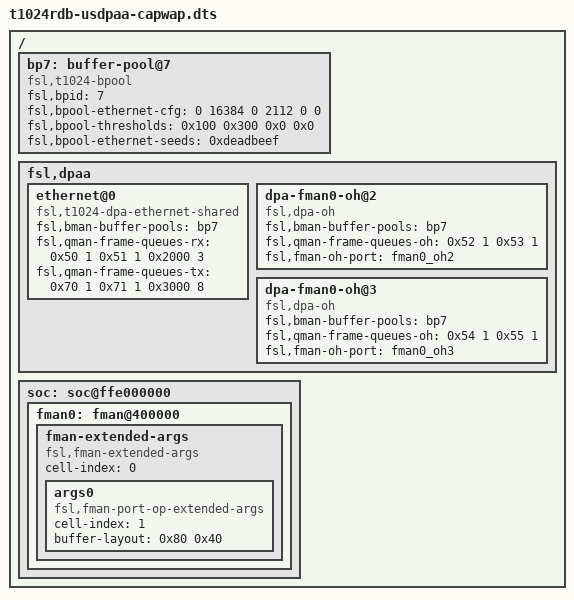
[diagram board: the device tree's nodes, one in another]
/*
 * T1024RDB CAPWAP Device Tree Source
 *
 * Copyright 2014 Freescale Semiconductor Inc.
 *
 * Redistribution and use in source and binary forms, with or without
 * modification, are permitted provided that the following conditions are met:
 *     * Redistributions of source code must retain the above copyright
 *       notice, this list of conditions and the following disclaimer.
 *     * Redistributions in binary form must reproduce the above copyright
 *       notice, this list of conditions and the following disclaimer in the
 *       documentation and/or other materials provided with the distribution.
 *     * Neither the name of Freescale Semiconductor nor the
 *       names of its contributors may be used to endorse or promote products
 *       derived from this software without specific prior written permission.
 *
 *
 * ALTERNATIVELY, this software may be distributed under the terms of the
 * GNU General Public License ("GPL") as published by the Free Software
 * Foundation, either version 2 of that License or (at your option) any
 * later version.
 *
 * THIS SOFTWARE IS PROVIDED BY Freescale Semiconductor ``AS IS'' AND ANY
 * EXPRESS OR IMPLIED WARRANTIES, INCLUDING, BUT NOT LIMITED TO, THE IMPLIED
 * WARRANTIES OF MERCHANTABILITY AND FITNESS FOR A PARTICULAR PURPOSE ARE
 * DISCLAIMED. IN NO EVENT SHALL Freescale Semiconductor BE LIABLE FOR ANY
 * DIRECT, INDIRECT, INCIDENTAL, SPECIAL, EXEMPLARY, OR CONSEQUENTIAL DAMAGES
 * (INCLUDING, BUT NOT LIMITED TO, PROCUREMENT OF SUBSTITUTE GOODS OR SERVICES;
 * LOSS OF USE, DATA, OR PROFITS; OR BUSINESS INTERRUPTION) HOWEVER CAUSED AND
 * ON ANY THEORY OF LIABILITY, WHETHER IN CONTRACT, STRICT LIABILITY, OR TORT
 * (INCLUDING NEGLIGENCE OR OTHERWISE) ARISING IN ANY WAY OUT OF THE USE OF THIS
 * SOFTWARE, EVEN IF ADVISED OF THE POSSIBILITY OF SUCH DAMAGE.
 */

/include/ "t1024rdb.dts"

/ {
	bp7: buffer-pool@7 {
		compatible = "fsl,t1024-bpool", "fsl,bpool";
		fsl,bpid = <7>;
		fsl,bpool-ethernet-cfg = <0 16384 0 2112 0 0>;
		fsl,bpool-thresholds = <0x100 0x300 0x0 0x0>;
		fsl,bpool-ethernet-seeds = <0xdeadbeef>;
	};

	fsl,dpaa {
		/* This DPAA port is used as CAPWAP Ethernet Port, which can be set when running
		   the use case by "-a 1,2", "1" is MAC ID, "2" is MAC type, the valid value of
		   type is: "1"--1G MAC, "2"--10G MAC. */
		ethernet@0 {
			compatible = "fsl,t1024-dpa-ethernet-shared", "fsl,dpa-ethernet-shared";
			fsl,bman-buffer-pools = <&bp7>;
			fsl,qman-frame-queues-rx = <0x50 1 0x51 1 0x2000 3>;
			fsl,qman-frame-queues-tx = <0x70 1 0x71 1 0x3000 8>;
		};
		/* The following two ports are used as Non-CAPWAP Ethernet ports, and should be
		   uncommented when the case running in Mode 2, using the following parameters
		   to set when running the case: "-s 3,1 -u 4,1 -m 2", "-m 2" means the case
		   runs in mode 2, "-s" and "-u" sperify two DPAA port, format is "MAC-ID,type",the
		   valid value of type is: "1"--1G MAC, "2"--10G MAC*/
/*
		ethernet@2 {
			compatible = "fsl,t1024-dpa-ethernet-init", "fsl,dpa-ethernet-init";
			fsl,bman-buffer-pools = <&bp7>;
			fsl,qman-frame-queues-rx = <0x58 1 0x59 1>;
			fsl,qman-frame-queues-tx = <0x72 1 0x73 1>;
		};
		ethernet@3 {
			compatible = "fsl,t1024-dpa-ethernet-init", "fsl,dpa-ethernet-init";
			fsl,bman-buffer-pools = <&bp7>;
			fsl,qman-frame-queues-rx = <0x60 1 0x61 1 >;
			fsl,qman-frame-queues-tx = <0x74 1 0x75 1 >;
		};
*/
		/* The following OP is used as outbound OP*/
		dpa-fman0-oh@2 {
			compatible = "fsl,dpa-oh";
			fsl,bman-buffer-pools = <&bp7>;
			/* Define frame queues for the OH port*/
			/* <OH Rx error, OH Rx default> */
			fsl,qman-frame-queues-oh = <0x52 1 0x53 1>;
			fsl,fman-oh-port = <&fman0_oh2>;
		};
		/* The following OP is used as inbound OP*/
		dpa-fman0-oh@3 {
			compatible = "fsl,dpa-oh";
			fsl,bman-buffer-pools = <&bp7>;
			/* Define frame queues for the OH port*/
			/* <OH Rx error, OH Rx default> */
			fsl,qman-frame-queues-oh = <0x54 1 0x55 1>;
			fsl,fman-oh-port = <&fman0_oh3>;
		};
	};

	soc: soc@ffe000000 {
		fman0: fman@400000 {
			fman-extended-args {
				compatible = "fsl,fman-extended-args";
				cell-index = <0>;
				/* Set 128bytes manip extra space for outbound(frgamentation) OP */
				args0 {
					cell-index = <1>;
					compatible = "fsl,fman-port-op-extended-args";
					/* manip_extra_space, data_align */
					buffer-layout = <0x80 0x40>;
				};
			};

		};
	};

};
